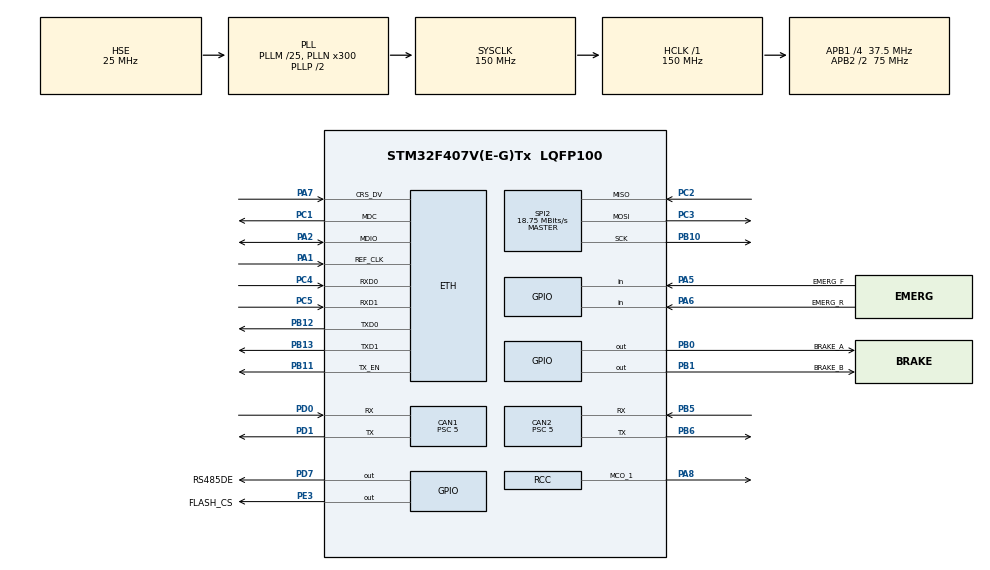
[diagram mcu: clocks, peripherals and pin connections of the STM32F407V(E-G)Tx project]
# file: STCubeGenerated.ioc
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CAN1.BS1=CAN_BS1_9TQ
CAN1.BS2=CAN_BS2_5TQ
CAN1.CalculateBaudRate=499999
CAN1.CalculateTimeBit=2000
CAN1.CalculateTimeQuantum=133.33333333333334
CAN1.NART=ENABLE
CAN1.Prescaler=5
CAN2.BS1=CAN_BS1_9TQ
CAN2.BS2=CAN_BS2_5TQ
CAN2.CalculateBaudRate=499999
CAN2.CalculateTimeBit=2000
CAN2.CalculateTimeQuantum=133.33333333333334
CAN2.NART=ENABLE
CAN2.Prescaler=5
ETH.AutoNegotiation=ETH_AUTONEGOTIATION_DISABLE
ETH.MediaInterface=ETH_MEDIA_INTERFACE_RMII
ETH.PHY_Name_RMII=DP83848_PHY_ADDRESS
ETH.RxMode=ETH_RXINTERRUPT_MODE
IWDG.Reload=1200
Mcu.Family=STM32F4
Mcu.Name=STM32F407V(E-G)Tx
Mcu.Package=LQFP100
NVIC.CAN1_RX0_IRQn=true\:3\:0\:true\:false\:true\:true\:true
NVIC.CAN1_RX1_IRQn=true\:3\:0\:true\:false\:true\:true\:true
NVIC.CAN2_RX0_IRQn=true\:3\:0\:true\:false\:true\:true\:true
NVIC.CAN2_RX1_IRQn=true\:3\:0\:true\:false\:true\:true\:true
NVIC.ETH_IRQn=true\:4\:0\:true\:false\:false\:false\:false
NVIC.PriorityGroup=NVIC_PRIORITYGROUP_4
NVIC.TIM5_IRQn=true\:7\:0\:true\:false\:true\:false\:true
NVIC.TimeBase=TIM5_IRQn
NVIC.TimeBaseIP=TIM5
PA1.Mode=RMII
PA1.Signal=ETH_REF_CLK
PA13.Mode=Serial_Wire
PA13.Signal=SYS_JTMS-SWDIO
PA14.Mode=Serial_Wire
PA14.Signal=SYS_JTCK-SWCLK
PA2.Mode=RMII
PA2.Signal=ETH_MDIO
PA5.GPIO_Label=EMERG_F
PA5.GPIO_PuPd=GPIO_PULLUP
PA5.Signal=GPIO_Input
PA6.GPIO_Label=EMERG_R
PA6.GPIO_PuPd=GPIO_PULLUP
PA6.Signal=GPIO_Input
PA7.Mode=RMII
PA7.Signal=ETH_CRS_DV
PA8.Mode=Clock-out-1
PA8.Signal=RCC_MCO_1
PB0.GPIO_Label=BRAKE_A
PB0.PinState=GPIO_PIN_SET
PB0.Signal=GPIO_Output
PB1.GPIO_Label=BRAKE_B
PB1.PinState=GPIO_PIN_SET
PB1.Signal=GPIO_Output
PB10.Mode=Full_Duplex_Master
PB10.Signal=SPI2_SCK
PB11.Mode=RMII
PB11.Signal=ETH_TX_EN
PB12.Mode=RMII
PB12.Signal=ETH_TXD0
PB13.Mode=RMII
PB13.Signal=ETH_TXD1
PB5.Mode=CAN_Activate
PB5.Signal=CAN2_RX
PB6.Mode=CAN_Activate
PB6.Signal=CAN2_TX
PC1.Mode=RMII
PC1.Signal=ETH_MDC
PC14-OSC32_IN.Mode=LSE-External-Oscillator
PC14-OSC32_IN.Signal=RCC_OSC32_IN
PC15-OSC32_OUT.Mode=LSE-External-Oscillator
PC15-OSC32_OUT.Signal=RCC_OSC32_OUT
PC2.Mode=Full_Duplex_Master
PC2.Signal=SPI2_MISO
PC3.Mode=Full_Duplex_Master
PC3.Signal=SPI2_MOSI
PC4.Mode=RMII
PC4.Signal=ETH_RXD0
PC5.Mode=RMII
PC5.Signal=ETH_RXD1
PD0.Mode=CAN_Activate
PD0.Signal=CAN1_RX
PD1.Mode=CAN_Activate
PD1.Signal=CAN1_TX
PD7.GPIO_Label=RS485DE
PD7.Signal=GPIO_Output
PE3.GPIO_Label=FLASH_CS
PE3.GPIO_Speed=GPIO_SPEED_FREQ_VERY_HIGH
PE3.PinState=GPIO_PIN_SET
PE3.Signal=GPIO_Output
PH0-OSC_IN.Mode=HSE-External-Oscillator
PH0-OSC_IN.Signal=RCC_OSC_IN
PH1-OSC_OUT.Mode=HSE-External-Oscillator
PH1-OSC_OUT.Signal=RCC_OSC_OUT
ProjectManager.HeapSize=0x200
ProjectManager.StackSize=0x200
ProjectManager.TargetToolchain=MDK-ARM V5.32
RCC.48MHZClocksFreq_Value=75000000
RCC.AHBFreq_Value=150000000
RCC.APB1CLKDivider=RCC_HCLK_DIV4
RCC.APB1Freq_Value=37500000
RCC.APB1TimFreq_Value=75000000
RCC.APB2CLKDivider=RCC_HCLK_DIV2
RCC.APB2Freq_Value=75000000
RCC.APB2TimFreq_Value=150000000
RCC.CortexFreq_Value=150000000
RCC.HCLKFreq_Value=150000000
RCC.HSE_VALUE=25000000
RCC.HSI_VALUE=16000000
RCC.PLLM=25
RCC.PLLN=300
RCC.PLLSourceVirtual=RCC_PLLSOURCE_HSE
RCC.RCC_MCO1Source=RCC_MCO1SOURCE_PLLCLK
RCC.RCC_MCODiv1=RCC_MCODIV_3
RCC.SYSCLKFreq_VALUE=150000000
RCC.SYSCLKSource=RCC_SYSCLKSOURCE_PLLCLK
RCC.VCOOutputFreq_Value=300000000
SPI2.CalculateBaudRate=18.75 MBits/s
SPI2.Direction=SPI_DIRECTION_2LINES
SPI2.Mode=SPI_MODE_MASTER
SPI2.VirtualType=VM_MASTER
VP_CRC_VS_CRC.Mode=CRC_Activate
VP_IWDG_VS_IWDG.Mode=IWDG_Activate
VP_SYS_VS_tim5.Mode=TIM5
board=custom

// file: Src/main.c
/* USER CODE BEGIN Header */
/**
  ******************************************************************************
  * @file           : main.c
  * @brief          : Main program body
  ******************************************************************************
  * @attention
  *
  * <h2><center>&copy; Copyright (c) 2020 STMicroelectronics.
  * All rights reserved.</center></h2>
  *
  * This software component is licensed by ST under BSD 3-Clause license,
  * the "License"; You may not use this file except in compliance with the
  * License. You may obtain a copy of the License at:
  *                        opensource.org/licenses/BSD-3-Clause
  *
  ******************************************************************************
  */
/* USER CODE END Header */
#include "main.h"

/* USER CODE BEGIN Includes */
#include "app_main.h"
/* USER CODE END Includes */

CAN_HandleTypeDef hcan1;
CAN_HandleTypeDef hcan2;

CRC_HandleTypeDef hcrc;

ETH_HandleTypeDef heth;

IWDG_HandleTypeDef hiwdg;

SPI_HandleTypeDef hspi2;

void SystemClock_Config(void);
static void MX_GPIO_Init(void);
static void MX_CAN1_Init(void);
static void MX_ETH_Init(void);
static void MX_IWDG_Init(void);
static void MX_CRC_Init(void);
static void MX_SPI2_Init(void);
static void MX_CAN2_Init(void);

int main(void)
{
  /* USER CODE BEGIN 1 */
	// Set vector table to main app start address.
	SCB->VTOR = FLASH_BASE | PROGRAM_OFFSET;
  /* USER CODE END 1 */

  /* MCU Configuration--------------------------------------------------------*/

  /* Reset of all peripherals, Initializes the Flash interface and the Systick. */
  HAL_Init();

  /* Configure the system clock */
  SystemClock_Config();

  /* Initialize all configured peripherals */
  MX_GPIO_Init();
  MX_CAN1_Init();
  MX_ETH_Init();
  MX_IWDG_Init();
  MX_CRC_Init();
  MX_SPI2_Init();
  MX_CAN2_Init();
  /* USER CODE BEGIN 2 */
    osKernelInitialize();
    InitAppMain();
    osKernelStart();
  /* USER CODE END 2 */

  /* Infinite loop */
    while (1)
    {

    }
}

void SystemClock_Config(void)
{
  RCC_OscInitTypeDef RCC_OscInitStruct = {0};
  RCC_ClkInitTypeDef RCC_ClkInitStruct = {0};

  /** Configure the main internal regulator output voltage
  */
  __HAL_RCC_PWR_CLK_ENABLE();
  __HAL_PWR_VOLTAGESCALING_CONFIG(PWR_REGULATOR_VOLTAGE_SCALE1);
  /** Initializes the RCC Oscillators according to the specified parameters
  * in the RCC_OscInitTypeDef structure.
  */
  RCC_OscInitStruct.OscillatorType = RCC_OSCILLATORTYPE_LSI|RCC_OSCILLATORTYPE_HSE;
  RCC_OscInitStruct.HSEState = RCC_HSE_ON;
  RCC_OscInitStruct.LSIState = RCC_LSI_ON;
  RCC_OscInitStruct.PLL.PLLState = RCC_PLL_ON;
  RCC_OscInitStruct.PLL.PLLSource = RCC_PLLSOURCE_HSE;
  RCC_OscInitStruct.PLL.PLLM = 25;
  RCC_OscInitStruct.PLL.PLLN = 300;
  RCC_OscInitStruct.PLL.PLLP = RCC_PLLP_DIV2;
  RCC_OscInitStruct.PLL.PLLQ = 4;
  if (HAL_RCC_OscConfig(&RCC_OscInitStruct) != HAL_OK)
  {
    Error_Handler();
  }
  /** Initializes the CPU, AHB and APB buses clocks
  */
  RCC_ClkInitStruct.ClockType = RCC_CLOCKTYPE_HCLK|RCC_CLOCKTYPE_SYSCLK
                              |RCC_CLOCKTYPE_PCLK1|RCC_CLOCKTYPE_PCLK2;
  RCC_ClkInitStruct.SYSCLKSource = RCC_SYSCLKSOURCE_PLLCLK;
  RCC_ClkInitStruct.AHBCLKDivider = RCC_SYSCLK_DIV1;
  RCC_ClkInitStruct.APB1CLKDivider = RCC_HCLK_DIV4;
  RCC_ClkInitStruct.APB2CLKDivider = RCC_HCLK_DIV2;

  if (HAL_RCC_ClockConfig(&RCC_ClkInitStruct, FLASH_LATENCY_4) != HAL_OK)
  {
    Error_Handler();
  }
  HAL_RCC_MCOConfig(RCC_MCO1, RCC_MCO1SOURCE_PLLCLK, RCC_MCODIV_3);
}

static void MX_CAN1_Init(void)
{

  hcan1.Instance = CAN1;
  hcan1.Init.Prescaler = 5;
  hcan1.Init.Mode = CAN_MODE_NORMAL;
  hcan1.Init.SyncJumpWidth = CAN_SJW_1TQ;
  hcan1.Init.TimeSeg1 = CAN_BS1_9TQ;
  hcan1.Init.TimeSeg2 = CAN_BS2_5TQ;
  hcan1.Init.TimeTriggeredMode = DISABLE;
  hcan1.Init.AutoBusOff = DISABLE;
  hcan1.Init.AutoWakeUp = DISABLE;
  hcan1.Init.AutoRetransmission = ENABLE;
  hcan1.Init.ReceiveFifoLocked = DISABLE;
  hcan1.Init.TransmitFifoPriority = DISABLE;
  if (HAL_CAN_Init(&hcan1) != HAL_OK)
  {
    Error_Handler();
  }

}

static void MX_CAN2_Init(void)
{

  hcan2.Instance = CAN2;
  hcan2.Init.Prescaler = 5;
  hcan2.Init.Mode = CAN_MODE_NORMAL;
  hcan2.Init.SyncJumpWidth = CAN_SJW_1TQ;
  hcan2.Init.TimeSeg1 = CAN_BS1_9TQ;
  hcan2.Init.TimeSeg2 = CAN_BS2_5TQ;
  hcan2.Init.TimeTriggeredMode = DISABLE;
  hcan2.Init.AutoBusOff = DISABLE;
  hcan2.Init.AutoWakeUp = DISABLE;
  hcan2.Init.AutoRetransmission = ENABLE;
  hcan2.Init.ReceiveFifoLocked = DISABLE;
  hcan2.Init.TransmitFifoPriority = DISABLE;
  if (HAL_CAN_Init(&hcan2) != HAL_OK)
  {
    Error_Handler();
  }

}

static void MX_CRC_Init(void)
{

  hcrc.Instance = CRC;
  if (HAL_CRC_Init(&hcrc) != HAL_OK)
  {
    Error_Handler();
  }

}

static void MX_ETH_Init(void)
{

   static uint8_t MACAddr[6];

  heth.Instance = ETH;
  heth.Init.AutoNegotiation = ETH_AUTONEGOTIATION_DISABLE;
  heth.Init.Speed = ETH_SPEED_100M;
  heth.Init.DuplexMode = ETH_MODE_FULLDUPLEX;
  heth.Init.PhyAddress = DP83848_PHY_ADDRESS;
  MACAddr[0] = 0x00;
  MACAddr[1] = 0x80;
  MACAddr[2] = 0xE1;
  MACAddr[3] = 0x00;
  MACAddr[4] = 0x00;
  MACAddr[5] = 0x00;
  heth.Init.MACAddr = &MACAddr[0];
  heth.Init.RxMode = ETH_RXINTERRUPT_MODE;
  heth.Init.ChecksumMode = ETH_CHECKSUM_BY_HARDWARE;
  heth.Init.MediaInterface = ETH_MEDIA_INTERFACE_RMII;

  if (HAL_ETH_Init(&heth) != HAL_OK)
  {
    Error_Handler();
  }

}

static void MX_IWDG_Init(void)
{

  hiwdg.Instance = IWDG;
  hiwdg.Init.Prescaler = IWDG_PRESCALER_4;
  hiwdg.Init.Reload = 1200;
  if (HAL_IWDG_Init(&hiwdg) != HAL_OK)
  {
    Error_Handler();
  }

}

static void MX_SPI2_Init(void)
{

  /* SPI2 parameter configuration*/
  hspi2.Instance = SPI2;
  hspi2.Init.Mode = SPI_MODE_MASTER;
  hspi2.Init.Direction = SPI_DIRECTION_2LINES;
  hspi2.Init.DataSize = SPI_DATASIZE_8BIT;
  hspi2.Init.CLKPolarity = SPI_POLARITY_LOW;
  hspi2.Init.CLKPhase = SPI_PHASE_1EDGE;
  hspi2.Init.NSS = SPI_NSS_SOFT;
  hspi2.Init.BaudRatePrescaler = SPI_BAUDRATEPRESCALER_2;
  hspi2.Init.FirstBit = SPI_FIRSTBIT_MSB;
  hspi2.Init.TIMode = SPI_TIMODE_DISABLE;
  hspi2.Init.CRCCalculation = SPI_CRCCALCULATION_DISABLE;
  hspi2.Init.CRCPolynomial = 10;
  if (HAL_SPI_Init(&hspi2) != HAL_OK)
  {
    Error_Handler();
  }

}

static void MX_GPIO_Init(void)
{
  LL_GPIO_InitTypeDef GPIO_InitStruct = {0};

  /* GPIO Ports Clock Enable */
  LL_AHB1_GRP1_EnableClock(LL_AHB1_GRP1_PERIPH_GPIOE);
  LL_AHB1_GRP1_EnableClock(LL_AHB1_GRP1_PERIPH_GPIOC);
  LL_AHB1_GRP1_EnableClock(LL_AHB1_GRP1_PERIPH_GPIOH);
  LL_AHB1_GRP1_EnableClock(LL_AHB1_GRP1_PERIPH_GPIOA);
  LL_AHB1_GRP1_EnableClock(LL_AHB1_GRP1_PERIPH_GPIOB);
  LL_AHB1_GRP1_EnableClock(LL_AHB1_GRP1_PERIPH_GPIOD);

  /**/
  LL_GPIO_SetOutputPin(FLASH_CS_GPIO_Port, FLASH_CS_Pin);

  /**/
  LL_GPIO_SetOutputPin(GPIOB, BRAKE_A_Pin|BRAKE_B_Pin);

  /**/
  LL_GPIO_ResetOutputPin(RS485DE_GPIO_Port, RS485DE_Pin);

  /**/
  GPIO_InitStruct.Pin = FLASH_CS_Pin;
  GPIO_InitStruct.Mode = LL_GPIO_MODE_OUTPUT;
  GPIO_InitStruct.Speed = LL_GPIO_SPEED_FREQ_VERY_HIGH;
  GPIO_InitStruct.OutputType = LL_GPIO_OUTPUT_PUSHPULL;
  GPIO_InitStruct.Pull = LL_GPIO_PULL_NO;
  LL_GPIO_Init(FLASH_CS_GPIO_Port, &GPIO_InitStruct);

  /**/
  GPIO_InitStruct.Pin = EMERG_F_Pin|EMERG_R_Pin;
  GPIO_InitStruct.Mode = LL_GPIO_MODE_INPUT;
  GPIO_InitStruct.Pull = LL_GPIO_PULL_UP;
  LL_GPIO_Init(GPIOA, &GPIO_InitStruct);

  /**/
  GPIO_InitStruct.Pin = BRAKE_A_Pin|BRAKE_B_Pin;
  GPIO_InitStruct.Mode = LL_GPIO_MODE_OUTPUT;
  GPIO_InitStruct.Speed = LL_GPIO_SPEED_FREQ_LOW;
  GPIO_InitStruct.OutputType = LL_GPIO_OUTPUT_PUSHPULL;
  GPIO_InitStruct.Pull = LL_GPIO_PULL_NO;
  LL_GPIO_Init(GPIOB, &GPIO_InitStruct);

  /**/
  GPIO_InitStruct.Pin = LL_GPIO_PIN_8;
  GPIO_InitStruct.Mode = LL_GPIO_MODE_ALTERNATE;
  GPIO_InitStruct.Speed = LL_GPIO_SPEED_FREQ_LOW;
  GPIO_InitStruct.OutputType = LL_GPIO_OUTPUT_PUSHPULL;
  GPIO_InitStruct.Pull = LL_GPIO_PULL_NO;
  GPIO_InitStruct.Alternate = LL_GPIO_AF_0;
  LL_GPIO_Init(GPIOA, &GPIO_InitStruct);

  /**/
  GPIO_InitStruct.Pin = RS485DE_Pin;
  GPIO_InitStruct.Mode = LL_GPIO_MODE_OUTPUT;
  GPIO_InitStruct.Speed = LL_GPIO_SPEED_FREQ_LOW;
  GPIO_InitStruct.OutputType = LL_GPIO_OUTPUT_PUSHPULL;
  GPIO_InitStruct.Pull = LL_GPIO_PULL_NO;
  LL_GPIO_Init(RS485DE_GPIO_Port, &GPIO_InitStruct);

}

void HAL_TIM_PeriodElapsedCallback(TIM_HandleTypeDef *htim)
{
  if (htim->Instance == TIM5) {
    HAL_IncTick();
  }
  /* USER CODE BEGIN Callback 1 */
  if (htim->Instance == TIM10) {

  }

  /* USER CODE END Callback 1 */
}

void Error_Handler(void)
{
}
